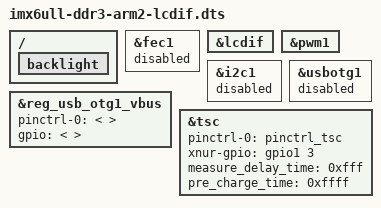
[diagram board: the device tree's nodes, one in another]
/*
 * Copyright (C) 2016 Freescale Semiconductor, Inc.
 *
 * This program is free software; you can redistribute it and/or modify
 * it under the terms of the GNU General Public License version 2 as
 * published by the Free Software Foundation.
 */

/* DTS file for LCDIF at imx6ull ddr3 arm2 board */

#include "imx6ull-ddr3-arm2.dts"

/ {
	backlight {
		status = "okay";
	};
};

&fec1 {
	status = "disabled";
};

&lcdif {
	status = "okay";
};

&pwm1 {
	status = "okay";
};

&i2c1 {
	status = "disabled";
};

&reg_usb_otg1_vbus {
	pinctrl-0 = < >;
	gpio = < >;
};

&usbotg1 {
	status = "disabled";
};

&tsc {
	pinctrl-names = "default";
	pinctrl-0 = <&pinctrl_tsc>;
	status = "okay";
	xnur-gpio = <&gpio1 3 0>;
	measure_delay_time = <0xfff>;
	pre_charge_time = <0xffff>;
};
